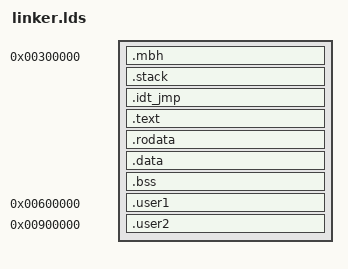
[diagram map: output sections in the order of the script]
/* GPLv2 (c) Airbus */
OUTPUT_FORMAT("elf32-i386","elf32-i386","elf32-i386");
OUTPUT_ARCH("i386")

ENTRY(entry)

PHDRS
{
   phboot  PT_LOAD FLAGS (7);
   phstack PT_LOAD FLAGS (6);
   phsetup PT_LOAD FLAGS (7);
}

SECTIONS
{
   . = 0x300000;
   .mbh      : { KEEP(*(.mbh)) . = ALIGN(4);     } : phboot
   .stack    : { KEEP(*(.stack))                 } : phstack

   __kernel_start__ = .;

   .idt_jmp  : { KEEP(*(.idt_jmp))               } : phsetup
   .text     : { *(.text)                        } : phsetup
   .rodata   : { *(.rodata)                      } : phsetup
   .data     : { *(.data)                        } : phsetup
   .bss      : { *(.bss COMMON)                  } : phsetup
   /DISCARD/ : { *(.note* .indent .comment)      } : phsetup

   . = 0x500000; 
   __kernel_end__ = .;

   . = 0x600000;
   __user1_start__ = .;
   .user1     : { *(.user1)                        } : phsetup
   __user1_end__ = .; 

   . = 0x900000; 
   __user2_start__ = .;
   .user2     : { *(.user2)                        } : phsetup
   __user2_end__ = .; 
   
}
